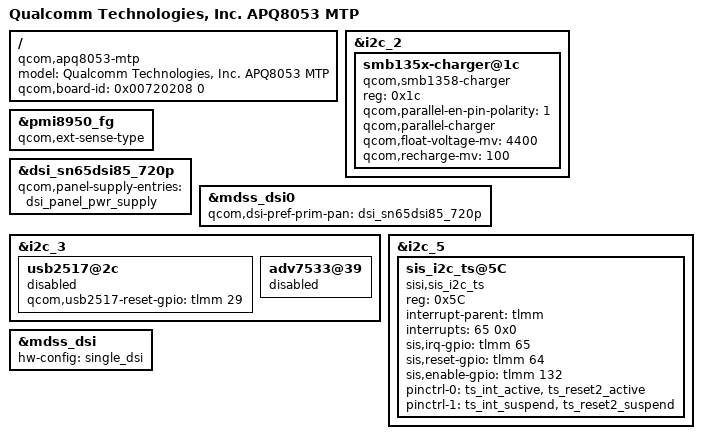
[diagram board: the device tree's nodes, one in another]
/*
 * Copyright (c) 2015-2016, The Linux Foundation. All rights reserved.
 *
 * This program is free software; you can redistribute it and/or modify
 * it under the terms of the GNU General Public License version 2 and
 * only version 2 as published by the Free Software Foundation.
 *
 * This program is distributed in the hope that it will be useful,
 * but WITHOUT ANY WARRANTY; without even the implied warranty of
 * MERCHANTABILITY or FITNESS FOR A PARTICULAR PURPOSE.  See the
 * GNU General Public License for more details.
 */

/dts-v1/;

#include "apq8053.dtsi"
#include "msm8953-mtp.dtsi"
#include "apq8053-oem.dtsi"
#include "apq8053-mtp-lvds-hdmi.dtsi"//Leo Guo add to support all panel in one image
#include "apq8053-mtp-aaio2.dtsi"
/ {
	model = "Qualcomm Technologies, Inc. APQ8053 MTP";
	compatible = "qcom,apq8053-mtp", "qcom,apq8053", "qcom,mtp";
	qcom,board-id= <0x00720208 0>;
};

&i2c_2 {
	/* Parallel-charger configuration */
	smb135x-charger@1c {
		compatible = "qcom,smb1358-charger";
		reg = <0x1c>;
		qcom,parallel-en-pin-polarity = <1>;
		qcom,parallel-charger;
		qcom,float-voltage-mv = <4400>;
		qcom,recharge-mv = <100>;
	};
};

&pmi8950_fg {
	/* use external rsense for parallel charging */
	qcom,ext-sense-type;
};
&dsi_sn65dsi85_720p {
	qcom,panel-supply-entries = <&dsi_panel_pwr_supply>;
};

&mdss_dsi0 {
	qcom,dsi-pref-prim-pan = <&dsi_sn65dsi85_720p>;
};

&i2c_3 {
	/*JackWLu: Add reset PIN for 10.1 I2.0 EVT2*/
	usb2517@2c {
		qcom,usb2517-reset-gpio = <&tlmm 29 0>; /*for HUB2.0 usb2517 reset pin*/
		status = "disabled";/*Value not use this setting*/
	};
};

&i2c_5 {
	status = "okay";
	/* sis touch configuration */
	sis_i2c_ts@5C {
		compatible = "sisi,sis_i2c_ts";
		reg = <0x5C>;
		interrupt-parent = <&tlmm>;
		interrupts = <65 0x0>;
		sis,irq-gpio= <&tlmm 65 0x00>;
		sis,reset-gpio= <&tlmm 64 0x00>;
		/* 2017/09/15, Jerry Zhai, enable 3v3 pin for sis touch */
		sis,enable-gpio= <&tlmm 132 0x00>;
		pinctrl-names = "pmx_ts_active","pmx_ts_suspend";
		pinctrl-0 = <&ts_int_active &ts_reset2_active>;
		pinctrl-1 = <&ts_int_suspend &ts_reset2_suspend>;
	};
};

/*20170920,Leo Guo add to disable HDMI for I20 value*/
&i2c_3 {
	adv7533@39 {
		status="disabled";
	};
};

&mdss_dsi {
	hw-config = "single_dsi";
};

